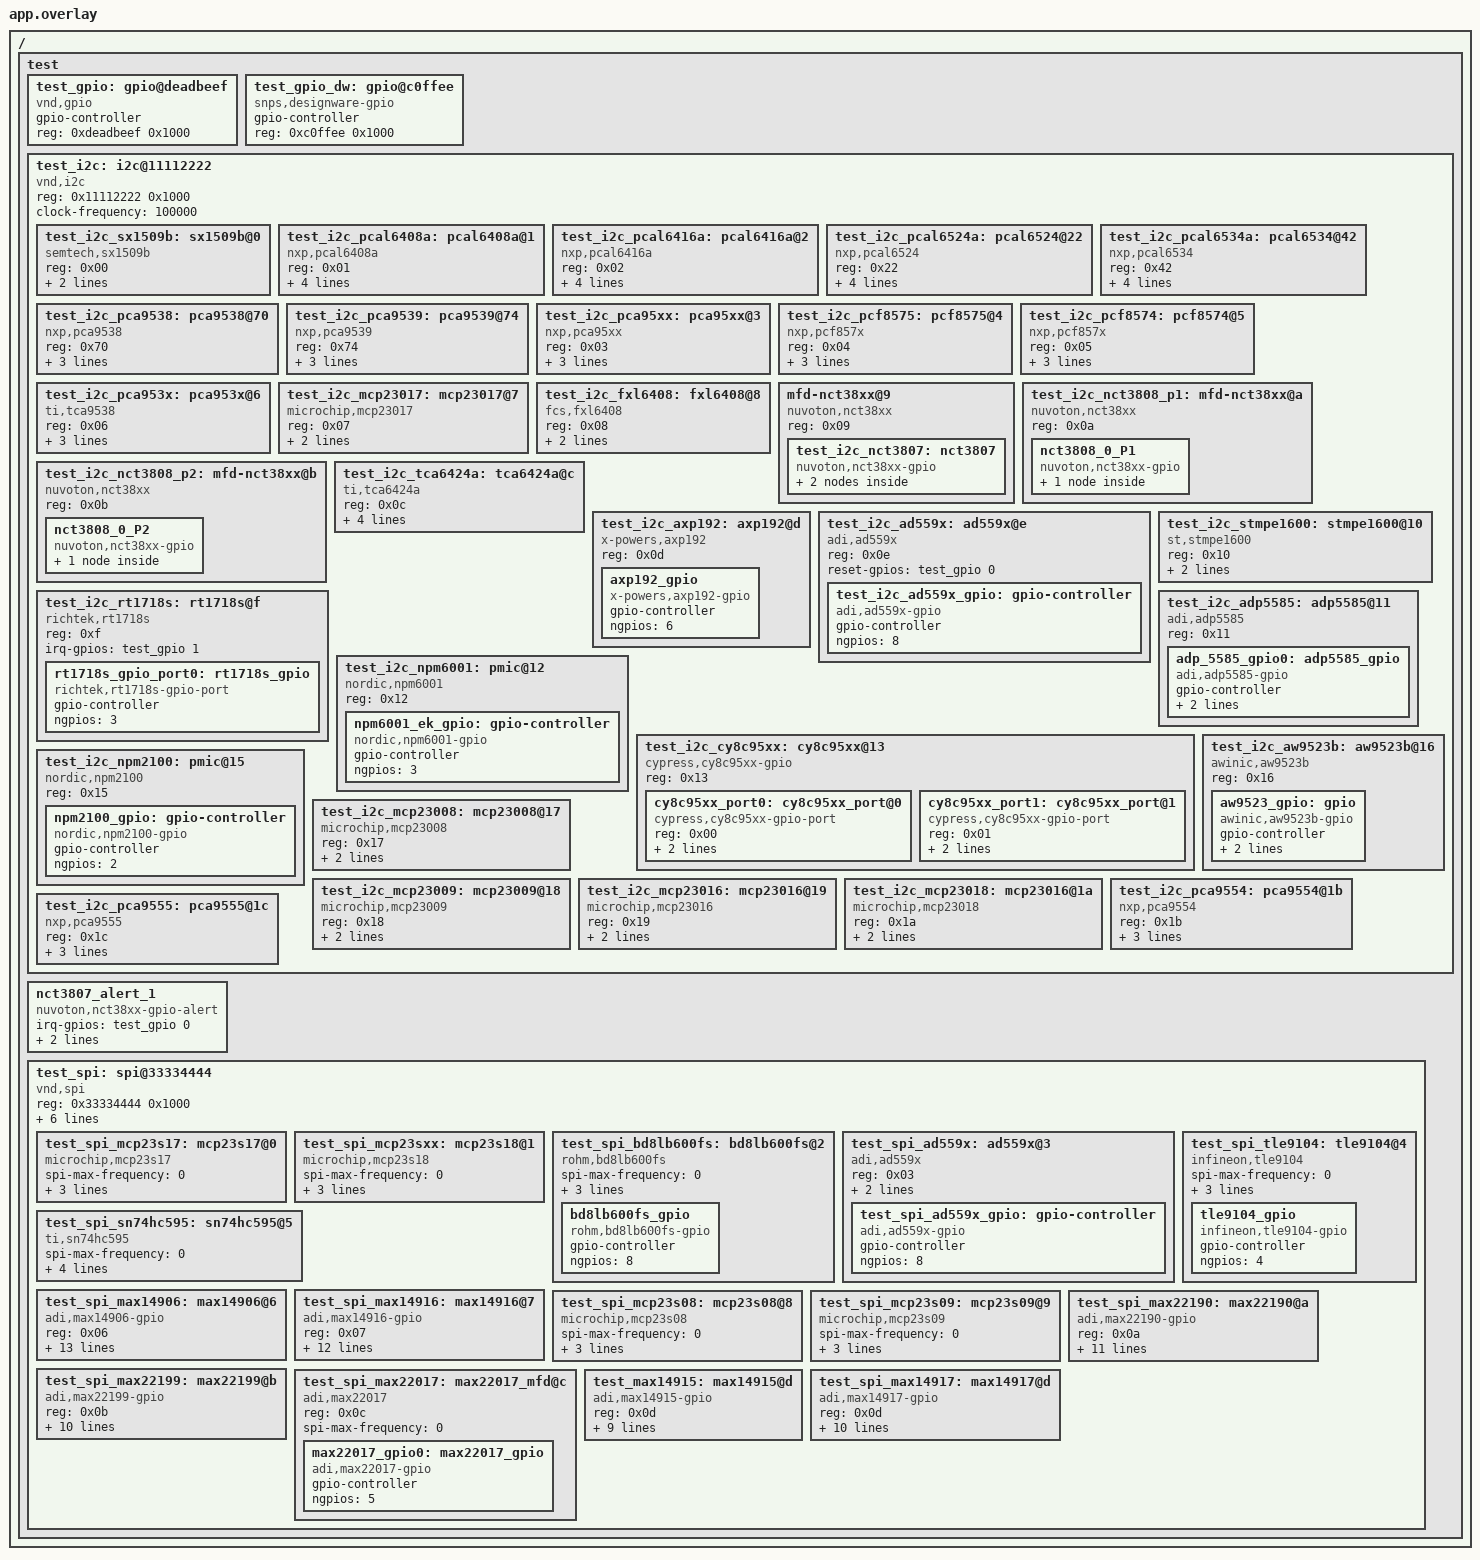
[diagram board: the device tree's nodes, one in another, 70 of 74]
/*
 * Copyright (c) 2020, Linaro Ltd.
 *
 * SPDX-License-Identifier: Apache-2.0
 *
 * Application overlay for testing driver builds
 *
 * Names in this file should be chosen in a way that won't conflict
 * with real-world devicetree nodes, to allow these tests to run on
 * (and be extended to test) real hardware.
 */

/ {
	test {
		#address-cells = <1>;
		#size-cells = <1>;

		test_gpio: gpio@deadbeef {
			compatible = "vnd,gpio";
			gpio-controller;
			reg = <0xdeadbeef 0x1000>;
			#gpio-cells = <0x2>;
			status = "okay";
		};

		test_gpio_dw: gpio@c0ffee {
			compatible = "snps,designware-gpio";
			gpio-controller;
			reg = <0xc0ffee 0x1000>;
			#gpio-cells = <0x2>;
			status = "okay";
		};

		test_i2c: i2c@11112222 {
			#address-cells = <1>;
			#size-cells = <0>;
			compatible = "vnd,i2c";
			reg = <0x11112222 0x1000>;
			status = "okay";
			clock-frequency = <100000>;

			test_i2c_sx1509b: sx1509b@0 {
				compatible = "semtech,sx1509b";
				reg = <0x00>;
				#gpio-cells = <2>;
				ngpios = <16>;
				gpio-controller;
			};

			test_i2c_pcal6408a: pcal6408a@1 {
				compatible = "nxp,pcal6408a";
				reg = <0x01>;
				gpio-controller;
				#gpio-cells = <2>;
				ngpios = <8>;
				int-gpios = <&test_gpio 0 0>;
				reset-gpios = <&test_gpio 0 0>;
			};

			test_i2c_pcal6416a: pcal6416a@2 {
				compatible = "nxp,pcal6416a";
				reg = <0x02>;
				gpio-controller;
				#gpio-cells = <2>;
				ngpios = <16>;
				int-gpios = <&test_gpio 0 0>;
				reset-gpios = <&test_gpio 0 0>;
			};

			test_i2c_pcal6524a: pcal6524@22 {
				compatible = "nxp,pcal6524";
				reg = <0x22>;
				gpio-controller;
				#gpio-cells = <2>;
				ngpios = <24>;
				int-gpios = <&test_gpio 0 0>;
				reset-gpios = <&test_gpio 0 0>;
			};

			test_i2c_pcal6534a: pcal6534@42 {
				compatible = "nxp,pcal6534";
				reg = <0x42>;
				gpio-controller;
				#gpio-cells = <2>;
				ngpios = <32>;
				int-gpios = <&test_gpio 0 0>;
				reset-gpios = <&test_gpio 0 0>;
			};

			test_i2c_pca9538: pca9538@70 {
				compatible = "nxp,pca9538";
				reg = <0x70>;
				gpio-controller;
				#gpio-cells = <2>;
				ngpios = <8>;
				int-gpios = <&test_gpio 0 0>;
			};

			test_i2c_pca9539: pca9539@74 {
				compatible = "nxp,pca9539";
				reg = <0x74>;
				gpio-controller;
				#gpio-cells = <2>;
				ngpios = <16>;
				int-gpios = <&test_gpio 0 0>;
			};

			test_i2c_pca95xx: pca95xx@3 {
				compatible = "nxp,pca95xx";
				reg = <0x03>;
				gpio-controller;
				#gpio-cells = <2>;
				ngpios = <16>;
				interrupt-gpios = <&test_gpio 0 0>;
			};

			test_i2c_pcf8575: pcf8575@4 {
				compatible = "nxp,pcf857x";
				reg = <0x04>;
				gpio-controller;
				#gpio-cells = <2>;
				ngpios = <16>;
				int-gpios = <&test_gpio 0 0>;
			};

			test_i2c_pcf8574: pcf8574@5 {
				compatible = "nxp,pcf857x";
				reg = <0x05>;
				gpio-controller;
				#gpio-cells = <2>;
				ngpios = <8>;
				int-gpios = <&test_gpio 0 0>;
			};

			test_i2c_pca953x: pca953x@6 {
				compatible = "ti,tca9538";
				reg = <0x06>;
				gpio-controller;
				#gpio-cells = <2>;
				ngpios = <8>;
				nint-gpios = <&test_gpio 0 0>;
			};

			test_i2c_mcp23017: mcp23017@7 {
				compatible = "microchip,mcp23017";
				reg = <0x07>;
				gpio-controller;
				#gpio-cells = <2>;
				ngpios = <16>;
			};

			test_i2c_fxl6408: fxl6408@8 {
				status = "okay";
				compatible = "fcs,fxl6408";
				reg = <0x08>;
				ngpios = <8>;
				#gpio-cells = <2>;
				gpio-controller;
			};

			mfd-nct38xx@9 {
				compatible = "nuvoton,nct38xx";
				reg = <0x09>;
				test_i2c_nct3807: nct3807 {
					#address-cells = <1>;
					#size-cells = <0>;
					compatible = "nuvoton,nct38xx-gpio";

					gpio@0 {
						compatible = "nuvoton,nct38xx-gpio-port";
						reg = <0x0>;
						gpio-controller;
						#gpio-cells = <2>;
						ngpios = <8>;
						pin-mask = <0xff>;
						pinmux-mask = <0xf7>;
					};

					gpio@1 {
						compatible = "nuvoton,nct38xx-gpio-port";
						reg = <0x1>;
						gpio-controller;
						#gpio-cells = <2>;
						ngpios = <8>;
						pin-mask = <0xff>;
					};
				};
			};

			test_i2c_nct3808_p1: mfd-nct38xx@a {
				compatible = "nuvoton,nct38xx";
				reg = <0x0a>;
				nct3808_0_P1 {
					#address-cells = <1>;
					#size-cells = <0>;
					compatible = "nuvoton,nct38xx-gpio";

					gpio@0 {
						compatible = "nuvoton,nct38xx-gpio-port";
						reg = <0x0>;
						gpio-controller;
						#gpio-cells = <2>;
						ngpios = <8>;
						pin-mask = <0xdc>;
						pinmux-mask = <0xff>;
					};
				};
			};

			test_i2c_nct3808_p2: mfd-nct38xx@b {
				compatible = "nuvoton,nct38xx";
				reg = <0x0b>;
				nct3808_0_P2 {
					#address-cells = <1>;
					#size-cells = <0>;
					compatible = "nuvoton,nct38xx-gpio";

					gpio@0 {
						compatible = "nuvoton,nct38xx-gpio-port";
						reg = <0x0>;
						gpio-controller;
						#gpio-cells = <2>;
						ngpios = <8>;
						pin-mask = <0xdc>;
						pinmux-mask = <0xff>;
					};
				};
			};

			test_i2c_tca6424a: tca6424a@c {
				compatible = "ti,tca6424a";
				reg = <0x0c>;
				gpio-controller;
				#gpio-cells = <2>;
				ngpios = <24>;
				int-gpios = <&test_gpio 0 0>;
				reset-gpios = <&test_gpio 0 0>;
			};

			test_i2c_axp192: axp192@d {
				compatible = "x-powers,axp192";
				reg = <0x0d>;

				axp192_gpio {
					compatible = "x-powers,axp192-gpio";
					gpio-controller;
					#gpio-cells = <2>;
					ngpios = <6>;
				};
			};

			test_i2c_ad559x: ad559x@e {
				compatible = "adi,ad559x";
				status = "okay";
				reg = <0x0e>;
				reset-gpios = <&test_gpio 0 0>;

				test_i2c_ad559x_gpio: gpio-controller {
					compatible = "adi,ad559x-gpio";
					gpio-controller;
					#gpio-cells = <2>;
					ngpios = <8>;
				};
			};

			test_i2c_rt1718s: rt1718s@f {
				compatible = "richtek,rt1718s";
				reg = <0xf>;
				irq-gpios = <&test_gpio 1 0>;

				rt1718s_gpio_port0: rt1718s_gpio {
					compatible = "richtek,rt1718s-gpio-port";

					gpio-controller;
					#gpio-cells = <2>;
					ngpios = <3>;
				};
			};

			test_i2c_stmpe1600: stmpe1600@10 {
				compatible = "st,stmpe1600";
				reg = <0x10>;
				ngpios = <16>;
				gpio-controller;
				#gpio-cells = <2>;
			};

			test_i2c_adp5585: adp5585@11 {
				compatible = "adi,adp5585";
				reg = <0x11>;
				status = "okay";

				adp_5585_gpio0: adp5585_gpio {
					compatible = "adi,adp5585-gpio";
					gpio-controller;
					#gpio-cells = <2>;
					ngpios = <13>;
					gpio-reserved-ranges = <5 3>;
					status = "okay";
				};
			};

			test_i2c_npm6001: pmic@12 {
				compatible = "nordic,npm6001";
				reg = <0x12>;

				npm6001_ek_gpio: gpio-controller {
					compatible = "nordic,npm6001-gpio";
					gpio-controller;
					#gpio-cells = <2>;
					ngpios = <3>;
				};
			};

			test_i2c_cy8c95xx: cy8c95xx@13 {
				compatible = "cypress,cy8c95xx-gpio";
				reg = <0x13>;
				ranges;
				#address-cells = <1>;
				#size-cells = <0>;

				cy8c95xx_port0: cy8c95xx_port@0 {
					compatible = "cypress,cy8c95xx-gpio-port";
					reg = <0x00>;
					gpio-controller;
					#gpio-cells = <2>;
					ngpios = <8>;
					status = "okay";
				};

				cy8c95xx_port1: cy8c95xx_port@1 {
					compatible = "cypress,cy8c95xx-gpio-port";
					reg = <0x01>;
					gpio-controller;
					#gpio-cells = <2>;
					ngpios = <8>;
					status = "okay";
				};
			};

			test_i2c_npm2100: pmic@15 {
				compatible = "nordic,npm2100";
				reg = <0x15>;

				npm2100_gpio: gpio-controller {
					compatible = "nordic,npm2100-gpio";
					gpio-controller;
					#gpio-cells = <2>;
					ngpios = <2>;
				};
			};

			test_i2c_aw9523b: aw9523b@16 {
				status = "okay";
				reg = <0x16>;
				compatible = "awinic,aw9523b";

				aw9523_gpio: gpio {
					compatible = "awinic,aw9523b-gpio";
					gpio-controller;
					#gpio-cells = <2>;
					int-gpios = <&test_gpio 0 0>;
					reset-gpios = <&test_gpio 0 0>;
				};
			};

			test_i2c_mcp23008: mcp23008@17 {
				compatible = "microchip,mcp23008";
				reg = <0x17>;
				gpio-controller;
				#gpio-cells = <2>;
				ngpios = <16>;
			};

			test_i2c_mcp23009: mcp23009@18 {
				compatible = "microchip,mcp23009";
				reg = <0x18>;
				gpio-controller;
				#gpio-cells = <2>;
				ngpios = <16>;
			};

			test_i2c_mcp23016: mcp23016@19 {
				compatible = "microchip,mcp23016";
				reg = <0x19>;
				gpio-controller;
				#gpio-cells = <2>;
				ngpios = <16>;
			};

			test_i2c_mcp23018: mcp23016@1a {
				compatible = "microchip,mcp23018";
				reg = <0x1a>;
				gpio-controller;
				#gpio-cells = <2>;
				ngpios = <16>;
			};

			test_i2c_pca9554: pca9554@1b {
				compatible = "nxp,pca9554";
				reg = <0x1b>;
				gpio-controller;
				#gpio-cells = <2>;
				ngpios = <8>;
				int-gpios = <&test_gpio 0 0>;
			};

			test_i2c_pca9555: pca9555@1c {
				compatible = "nxp,pca9555";
				reg = <0x1c>;
				gpio-controller;
				#gpio-cells = <2>;
				ngpios = <16>;
				int-gpios = <&test_gpio 0 0>;
			};
		};

		nct3807_alert_1 {
			compatible = "nuvoton,nct38xx-gpio-alert";
			irq-gpios = <&test_gpio 0 0>;
			nct38xx-dev = <&test_i2c_nct3808_p1 &test_i2c_nct3808_p2>;
		};

		test_spi: spi@33334444 {
			#address-cells = <1>;
			#size-cells = <0>;
			compatible = "vnd,spi";
			reg = <0x33334444 0x1000>;
			status = "okay";
			clock-frequency = <2000000>;

			/* one entry for every devices at spi.dtsi */
			cs-gpios = <&test_gpio 0 0
				    &test_gpio 0 0
				    &test_gpio 0 0
				    &test_gpio 0 0
				    &test_gpio 0 0
				    &test_gpio 0 0
				    &test_gpio 0 0
				    &test_gpio 0 0
				    &test_gpio 0 0
				    &test_gpio 0 0
				    &test_gpio 0 0
				    &test_gpio 0 0>;

			test_spi_mcp23s17: mcp23s17@0 {
				compatible = "microchip,mcp23s17";
				spi-max-frequency = <0>;
				reg = <0x0>;
				gpio-controller;
				#gpio-cells = <2>;
				ngpios = <16>;
			};

			test_spi_mcp23sxx: mcp23s18@1 {
				compatible = "microchip,mcp23s18";
				spi-max-frequency = <0>;
				reg = <0x01>;
				gpio-controller;
				#gpio-cells = <2>;
				ngpios = <16>;
			};

			test_spi_bd8lb600fs: bd8lb600fs@2 {
				compatible = "rohm,bd8lb600fs";
				status = "okay";
				spi-max-frequency = <0>;
				reg = <0x02>;
				reset-gpios = <&test_gpio 0 0>;
				instance-count = <1>;

				bd8lb600fs_gpio: bd8lb600fs_gpio {
					compatible = "rohm,bd8lb600fs-gpio";
					status = "okay";
					gpio-controller;
					#gpio-cells = <2>;
					ngpios = <8>;
				};
			};

			test_spi_ad559x: ad559x@3 {
				compatible = "adi,ad559x";
				status = "okay";
				reg = <0x03>;
				spi-max-frequency = <0>;
				reset-gpios = <&test_gpio 0 0>;

				test_spi_ad559x_gpio: gpio-controller {
					compatible = "adi,ad559x-gpio";
					gpio-controller;
					#gpio-cells = <2>;
					ngpios = <8>;
				};
			};

			test_spi_tle9104: tle9104@4 {
				compatible = "infineon,tle9104";
				status = "okay";
				spi-max-frequency = <0>;
				reg = <0x04>;
				resn-gpios = <&test_gpio 0 0>;
				en-gpios = <&test_gpio 0 0>;

				tle9104_gpio: tle9104_gpio {
					compatible = "infineon,tle9104-gpio";
					status = "okay";
					gpio-controller;
					#gpio-cells = <2>;
					ngpios = <4>;
				};
			};

			test_spi_sn74hc595: sn74hc595@5 {
				compatible = "ti,sn74hc595";
				status = "okay";
				spi-max-frequency = <0>;
				reg = <0x05>;

				gpio-controller;
				reset-gpios = <&test_gpio 0 0>;
				ngpios = <8>;
				#gpio-cells = <2>;
			};

			test_spi_max14906: max14906@6 {
				compatible = "adi,max14906-gpio";
				status = "okay";
				reg = <0x06>;
				spi-max-frequency = <0>;
				gpio-controller;
				#gpio-cells = <2>;
				ngpios = <4>;
				crc-en;
				spi-addr = <0>;
				ow-en = <0 0 0 0>;
				vdd-ov-en = <0 0 0 0>;
				gdrv-en = <0 0 0 0>;
				sh-vdd-en = <0 0 0 0>;
				drdy-gpios = <&test_gpio 0 0>;
				fault-gpios = <&test_gpio 0 0>;
				sync-gpios = <&test_gpio 0 0>;
				en-gpios = <&test_gpio 0 0>;
			};

			test_spi_max14916: max14916@7 {
				compatible = "adi,max14916-gpio";
				status = "okay";
				reg = <0x07>;
				spi-max-frequency = <0>;
				gpio-controller;
				#gpio-cells = <2>;
				ngpios = <8>;
				crc-en;
				spi-addr = <0>;
				ow-on-en = <0 0 0 0>;
				ow-off-en = <0 0 0 0>;
				sh-vdd-en = <0 0 0 0>;
				drdy-gpios = <&test_gpio 0 0>;
				fault-gpios = <&test_gpio 0 0>;
				sync-gpios = <&test_gpio 0 0>;
				en-gpios = <&test_gpio 0 0>;
			};

			test_spi_mcp23s08: mcp23s08@8 {
				compatible = "microchip,mcp23s08";
				spi-max-frequency = <0>;
				reg = <0x08>;
				gpio-controller;
				#gpio-cells = <2>;
				ngpios = <16>;
			};

			test_spi_mcp23s09: mcp23s09@9 {
				compatible = "microchip,mcp23s09";
				spi-max-frequency = <0>;
				reg = <0x09>;
				gpio-controller;
				#gpio-cells = <2>;
				ngpios = <16>;
			};

			test_spi_max22190: max22190@a {
				compatible = "adi,max22190-gpio";
				status = "okay";
				reg = <0x0a>;
				spi-max-frequency = <0>;
				gpio-controller;
				#gpio-cells = <2>;
				ngpios = <8>;
				max22190-mode = <1>;
				filter-wbes = <1 0 1 0  1 0 1 0>;
				filter-fbps = <0 0 0 0  0 0 0 0>;
				filter-delays = <50 100 400 800 1600 3200 12800 20000>;
				drdy-gpios = <&test_gpio 0 0>;
				fault-gpios = <&test_gpio 0 0>;
				latch-gpios = <&test_gpio 0 0>;
			};

			test_spi_max22199: max22199@b {
				compatible = "adi,max22199-gpio";
				status = "okay";
				reg = <0x0b>;
				spi-max-frequency = <0>;
				gpio-controller;
				#gpio-cells = <2>;
				ngpios = <8>;
				max22190-mode = <1>;
				filter-fbps = <0 0 0 0  0 0 0 0>;
				filter-delays = <50 100 400 800 1600 3200 12800 20000>;
				drdy-gpios = <&test_gpio 0 0>;
				fault-gpios = <&test_gpio 0 0>;
				latch-gpios = <&test_gpio 0 0>;
			};

			test_spi_max22017: max22017_mfd@c {
				compatible = "adi,max22017";
				status = "okay";
				reg = <0x0c>;
				spi-max-frequency = <0>;

				max22017_gpio0: max22017_gpio {
					compatible = "adi,max22017-gpio";
					status = "okay";
					gpio-controller;
					ngpios = <5>;
					#gpio-cells = <2>;
				};
			};

			test_max14915: max14915@d {
				compatible = "adi,max14915-gpio";
				status = "okay";
				reg = <0x0d>;
				spi-max-frequency = <0>;
				gpio-controller;
				#gpio-cells = <2>;
				ngpios = <8>;
				crc-en;
				spi-addr = <0>;
				drdy-gpios = <&test_gpio 0 0>;
				fault-gpios = <&test_gpio 0 0>;
				sync-gpios = <&test_gpio 0 0>;
				en-gpios = <&test_gpio 0 0>;
			};

			test_spi_max14917: max14917@d {
				compatible = "adi,max14917-gpio";
				status = "okay";
				reg = <0x0d>;
				spi-max-frequency = <0>;
				gpio-controller;
				#gpio-cells = <2>;
				ngpios = <8>;
				vddok-gpios = <&test_gpio 0 0>;
				ready-gpios = <&test_gpio 0 0>;
				comerr-gpios = <&test_gpio 0 0>;
				fault-gpios = <&test_gpio 0 0>;
				en-gpios = <&test_gpio 0 0>;
				sync-gpios = <&test_gpio 0 0>;
				crcen-gpios = <&test_gpio 0 0>;
			};
		};
	};
};
